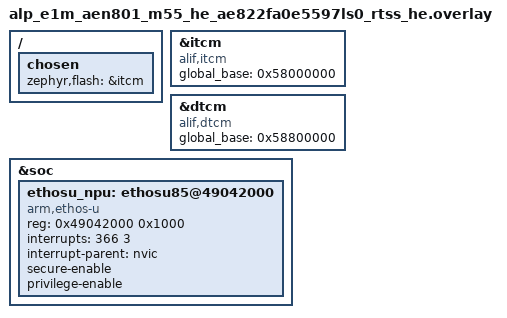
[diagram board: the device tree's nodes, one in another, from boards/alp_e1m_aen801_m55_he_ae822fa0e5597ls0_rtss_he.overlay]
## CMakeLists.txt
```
# Copyright (c) 2026 Alp Lab AB
# SPDX-License-Identifier: Apache-2.0
#
# aen-inference-latency -- on-target inference LATENCY benchmark for the
# E1M-AEN801 / AEN803 (Ensemble E8, M55-HE).  Runs a Vela-compiled int8 model
# in timed windows and prints cycles + milliseconds per inference and the
# tensor-arena high-water mark.  No rail monitor, no I2C: it needs nothing but
# the console, so it runs on any board and fits the Flow C ITCM RAM-run path
# for small models.  Its console protocol is the ENERGY-CFG / ENERGY-W subset
# that `tan model run --device --capture` parses (see src/main.cpp).
#
# The NPU build wiring is IDENTICAL to examples/aen/aen-inference-energy and
# the silicon-proven examples/aen/aen-npu-inference-alif, and reuses that
# app's gen_model.py rather than copying it (one Vela invocation, one hardware
# fact).  Only the model-gen script is shared; every config file here is local.
#
# Modules required at build time (pass via -DEXTRA_ZEPHYR_MODULES):
#   the alp-sdk checkout, hal_alif, hal/ethos_u, lib/tflite-micro
# the AEN bench build helper passes the first two automatically.

cmake_minimum_required(VERSION 3.20.0)

find_package(Zephyr REQUIRED HINTS $ENV{ZEPHYR_BASE})
project(aen_inference_latency LANGUAGES C CXX)

set(AEN_NPU_INFERENCE_DIR "${CMAKE_CURRENT_SOURCE_DIR}/../aen-npu-inference-alif"
    CACHE PATH "Sibling example whose gen_model.py (the Vela driver) is SHARED, not copied")

# Fail with the actual reason.  Copying this example out of the SDK tree -- the
# normal customer path -- leaves the sibling behind, and without this check the
# build dies as an opaque "model-gen failed (rc=1)" from the custom command.
if(NOT EXISTS "${AEN_NPU_INFERENCE_DIR}/gen_model.py")
	message(FATAL_ERROR
		"aen-inference-latency: cannot find ${AEN_NPU_INFERENCE_DIR}/gen_model.py.\n"
		"This example deliberately SHARES the Vela driver script with "
		"examples/aen/aen-npu-inference-alif rather than copying it, so the two "
		"cannot drift.  Keep both example directories together, or point "
		"-DAEN_NPU_INFERENCE_DIR=<path to aen-npu-inference-alif> at it.")
endif()

# --------------------------------------------------------------------------
# Model-gen: Vela-compile the fixture for the U85 with the Alif system-config.
# --------------------------------------------------------------------------
set(AEN_NPU_VELA   "vela"
    CACHE FILEPATH "Vela compiler executable (on PATH, or override: -DAEN_NPU_VELA=<venv>/bin/vela)")
set(AEN_NPU_ACCEL  "ethos-u85-256"
    CACHE STRING   "Vela --accelerator-config (the AEN801 U85 is 256-MAC)")
set(AEN_NPU_MODEL  "${CMAKE_CURRENT_SOURCE_DIR}/../../../tests/fixtures/models/tiny_int8.tflite"
    CACHE FILEPATH "Input int8 .tflite to Vela-compile")
set(AEN_NPU_MODEL_NAME "tiny_int8_fixture"
    CACHE STRING   "Embedded model identity string")

# ALIF PROPRIETARY Vela config -- NOT redistributed by alp-sdk.  Obtain it from
# alp-sdk-internal and pass -DAEN_NPU_VELA_CONFIG=<path>/ensemble_vela.ini.
# When unset, Vela uses its built-in system-config; the app still runs on the
# NPU (src/main.cpp pins every region to the SRAM AXI port, which is what the
# SRAM_Only layout needs), but the command stream is not the bench-matched one.
set(AEN_NPU_VELA_CONFIG ""
    CACHE FILEPATH "Path to the Alif Vela config .ini (ALIF PROPRIETARY -- from alp-sdk-internal)")
set(AEN_NPU_SYSTEM_CONFIG "Ethos_U85_SRAM_Only"
    CACHE STRING   "Vela --system-config (HE core, single SRAM region)")
set(AEN_NPU_MEMORY_MODE   "Sram_Only"
    CACHE STRING   "Vela --memory-mode (single region -> SRAM0)")

set(AEN_NPU_GEN_DIR "${CMAKE_CURRENT_BINARY_DIR}/model-gen")
set(AEN_NPU_MODEL_H "${AEN_NPU_GEN_DIR}/model.h")

set(_gen_args
	--vela          ${AEN_NPU_VELA}
	--accel         ${AEN_NPU_ACCEL}
	--model         ${AEN_NPU_MODEL}
	--name          ${AEN_NPU_MODEL_NAME}
	--build-dir     ${AEN_NPU_GEN_DIR}
	--out           ${AEN_NPU_MODEL_H}
)
# --system-config/--memory-mode name sections that live ONLY in the Alif
# proprietary ensemble_vela.ini, so pass them ONLY when that config is supplied
# -- else Vela errors "Section ... not found" against its built-in vela.ini.
if(AEN_NPU_VELA_CONFIG)
	list(APPEND _gen_args --config ${AEN_NPU_VELA_CONFIG}
	     --system-config ${AEN_NPU_SYSTEM_CONFIG} --memory-mode ${AEN_NPU_MEMORY_MODE})
endif()

add_custom_command(
	OUTPUT  ${AEN_NPU_MODEL_H}
	COMMAND ${CMAKE_COMMAND} -E make_directory ${AEN_NPU_GEN_DIR}
	COMMAND ${PYTHON_EXECUTABLE} ${AEN_NPU_INFERENCE_DIR}/gen_model.py ${_gen_args}
	DEPENDS ${AEN_NPU_MODEL} ${AEN_NPU_INFERENCE_DIR}/gen_model.py
	COMMENT "aen-inference-latency: Vela-compiling ${AEN_NPU_MODEL} for ${AEN_NPU_ACCEL}"
	VERBATIM
)

# Configure-time generation (so the include path resolves on the first build).
if(NOT EXISTS ${AEN_NPU_MODEL_H})
	execute_process(
		COMMAND ${CMAKE_COMMAND} -E make_directory ${AEN_NPU_GEN_DIR}
		COMMAND ${PYTHON_EXECUTABLE} ${AEN_NPU_INFERENCE_DIR}/gen_model.py ${_gen_args}
		RESULT_VARIABLE _gen_rc
	)
	if(NOT _gen_rc EQUAL 0)
		message(FATAL_ERROR "aen-inference-latency: model-gen failed (rc=${_gen_rc})")
	endif()
endif()

add_custom_target(aen_latency_model DEPENDS ${AEN_NPU_MODEL_H})
add_dependencies(app aen_latency_model)

# Publish hal_alif's common/include so <soc_memory_map.h> (local_to_global())
# resolves.  hal_alif adds it only under CONFIG_RTSS_HE/HP, but that same gate
# also compiles TrustZone sources that hard-#error without a non-secure DTS
# node this RAM-run board does not have -- so publish just the headers.
zephyr_include_directories(${ZEPHYR_ALIF_MODULE_DIR}/common/include)

target_include_directories(app PRIVATE ${AEN_NPU_GEN_DIR})
target_sources(app PRIVATE src/main.cpp)

# --------------------------------------------------------------------------
# Benchmark knobs -> preprocessor defines.  A `-DFOO=bar` on the cmake command
# line only sets a CACHE variable; it reaches the compiler only through this
# forwarding.  Each is left EMPTY so src/main.cpp keeps its own #ifndef default.
# --------------------------------------------------------------------------
set(AEN_LATENCY_WINDOWS "" CACHE STRING
    "Timed windows to run (default 5, max 6: RAM console size)")
set(AEN_LATENCY_INFERENCES "" CACHE STRING
    "Inferences per window (default 20)")
set(AEN_LATENCY_WINDOW_MAX_MS "" CACHE STRING
    "Per-window wall-time cap in ms, must stay under the 26.8 s cycle-counter wrap (default 10000)")

foreach(_knob AEN_LATENCY_WINDOWS AEN_LATENCY_INFERENCES AEN_LATENCY_WINDOW_MAX_MS)
	if(NOT "${${_knob}}" STREQUAL "")
		target_compile_definitions(app PRIVATE ${_knob}=${${_knob}})
		message(STATUS "aen-inference-latency: ${_knob}=${${_knob}}")
	endif()
endforeach()
```

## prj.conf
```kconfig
# SPDX-License-Identifier: Apache-2.0
#
# aen-inference-latency -- per-inference latency of a Vela-compiled model on the
# E1M-AEN801 / AEN803 Ethos-U85 (M55-HE).  The NPU stack below is transcribed
# from examples/aen/aen-inference-energy / aen-npu-inference-alif
# (silicon-proven); this app adds no I2C and no chip driver.

# --- TFLM + Ethos-U stack (see aen-npu-inference-alif for the derivation) ---

# TFLM is C++17; the MicroInterpreter is C++.
CONFIG_CPP=y
CONFIG_STD_CPP17=y

# TFLM module + the Ethos-U custom-op kernel that dispatches onto the NPU.
CONFIG_TENSORFLOW_LITE_MICRO=y

# The Arm Ethos-U core driver + the Zephyr frontend that instantiates the
# arm,ethos-u node at POST_KERNEL.  CONFIG_ARM_ETHOS_U stays unset for the same
# reason as aen-inference-energy: src/main.cpp provides the address remap.
CONFIG_ETHOS_U=y
CONFIG_ETHOS_U_DCACHE=y

# The AE822 (E8) NPU is an Ethos-U85, 256-MAC.
CONFIG_ETHOS_U85_256=y

# --- Heap / stack -----------------------------------------------------------

CONFIG_HEAP_MEM_POOL_SIZE=65536
CONFIG_MAIN_STACK_SIZE=16384

# --- DMA correctness --------------------------------------------------------

# The NPU is a DMA master; DCACHE=n keeps the CPU and NPU views coherent.
CONFIG_DCACHE=n

# --- Console: RAM console ----------------------------------------------------

# The whole capture is a few KB (header + one ENERGY-W and a handful of
# per-inference lines per window), so 8 KiB with headroom replaces
# aen-inference-energy's 64 KiB sample-stream buffer.  A truncated RAM console
# reads as a shorter capture, so the size is generous on purpose.  The buffer is
# DTCM (not the ITCM image), so it does not eat the Flow C budget.
# Read back with the AEN RAM-run helper; for a large model use the Flow D
# overlay in flowd/ and read the console over SWD/UART as usual.
CONFIG_CONSOLE=y
CONFIG_RAM_CONSOLE=y
CONFIG_RAM_CONSOLE_BUFFER_SIZE=8192
CONFIG_UART_CONSOLE=n
CONFIG_STDOUT_CONSOLE=y
CONFIG_PRINTK=y

# ms-per-inference is printed as a decimal; the ENERGY-CFG header carries the
# measured arena sizes as integers, but the per-window mean latency uses %f.
CONFIG_CBPRINTF_FP_SUPPORT=y

# Logging off: deferred log mode has no ram_console backend and would eat the
# printk protocol lines.
CONFIG_LOG=n
```

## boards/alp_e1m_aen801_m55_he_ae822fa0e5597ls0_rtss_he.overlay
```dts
/*
 * Copyright (c) 2026 Alp Lab AB
 * SPDX-License-Identifier: Apache-2.0
 *
 * aen-inference-latency overlay for the E1M-AEN801 (Ensemble E8, M55-HE)
 * bench RAM-run.  Only the NPU half of aen-inference-energy's overlay: the
 * ITCM retarget + itcm/dtcm global_base + the Ethos-U85 node, transcribed from
 * examples/aen/aen-npu-inference-alif (silicon-proven).  There is deliberately
 * no I2C2 / pinctrl half -- this app has no rail monitor.
 */
/*
 * RAM-run: the SoC `select` puts code in XIP; retarget ROM to ITCM so the
 * image links + runs from RAM (J-Link loadbin+go, no reset).  PATH-REFERENCE
 * form (&itcm) -- the phandle-array form <&itcm> makes FLASH_SIZE=0 and the
 * image overflows the (empty) FLASH region at link time.
 */
/ {
	chosen {
		zephyr,flash = &itcm;
		/delete-property/ zephyr,code-partition;
	};
};

/*
 * global_base for hal_alif's local_to_global() (soc_memory_map.h), which the
 * strong ethosu_address_remap in src/main.cpp calls.  The board's upstream
 * itcm/dtcm nodes are compatible "arm,itcm"/"arm,dtcm", whose binding has no
 * global_base, so re-`compatible` them onto the alp-sdk alif,itcm/alif,dtcm
 * bindings (which declare it) and set the E8 RTSS-HE global views, transcribed
 * from the Apache-2.0 zephyr_alif fork
 * (dts/arm/alif/ensemble/common/ensemble_rtss_he.dtsi):
 *     ITCM global_base = 0x58000000, DTCM global_base = 0x58800000.
 * reg / zephyr,memory-region are unchanged, so the linker regions and the
 * RAM-run retarget above are unaffected.
 */
&itcm {
	compatible = "alif,itcm";
	global_base = <0x58000000>;
};

&dtcm {
	compatible = "alif,dtcm";
	global_base = <0x58800000>;
};

&soc {
	/*
	 * Arm Ethos-U85 NPU.  compatible "arm,ethos-u", driven by the Arm
	 * Ethos-U core driver's Zephyr frontend (drivers/misc/ethos_u).
	 * Base 0x49042000, IRQ 366 + secure/privilege flags transcribed
	 * verbatim from the fork node (e4_e6_e8.dtsi ethosu1).  No `clocks`
	 * property: the fork's ethosu85 node carries none, and regcheck already
	 * confirmed the block is clocked (device_is_ready=1, ID=0x20007001).
	 */
	ethosu_npu: ethosu85@49042000 {
		compatible = "arm,ethos-u";
		reg = <0x49042000 0x1000>;
		interrupts = <366 3>;
		interrupt-parent = <&nvic>;
		secure-enable;
		privilege-enable;
		status = "okay";
	};
};
```

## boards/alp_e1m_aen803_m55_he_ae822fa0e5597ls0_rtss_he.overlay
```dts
/*
 * Copyright (c) 2026 Alp Lab AB
 * SPDX-License-Identifier: Apache-2.0
 *
 * aen-inference-latency overlay for the E1M-AEN803 (Ensemble E8, M55-HE)
 * bench RAM-run.  Only the NPU half of aen-inference-energy's overlay: the
 * ITCM retarget + itcm/dtcm global_base + the Ethos-U85 node, transcribed from
 * examples/aen/aen-npu-inference-alif (silicon-proven).  There is deliberately
 * no I2C2 / pinctrl half -- this app has no rail monitor.
 */
/*
 * RAM-run: the SoC `select` puts code in XIP; retarget ROM to ITCM so the
 * image links + runs from RAM (J-Link loadbin+go, no reset).  PATH-REFERENCE
 * form (&itcm) -- the phandle-array form <&itcm> makes FLASH_SIZE=0 and the
 * image overflows the (empty) FLASH region at link time.
 */
/ {
	chosen {
		zephyr,flash = &itcm;
		/delete-property/ zephyr,code-partition;
	};
};

/*
 * global_base for hal_alif's local_to_global() (soc_memory_map.h), which the
 * strong ethosu_address_remap in src/main.cpp calls.  The board's upstream
 * itcm/dtcm nodes are compatible "arm,itcm"/"arm,dtcm", whose binding has no
 * global_base, so re-`compatible` them onto the alp-sdk alif,itcm/alif,dtcm
 * bindings (which declare it) and set the E8 RTSS-HE global views, transcribed
 * from the Apache-2.0 zephyr_alif fork
 * (dts/arm/alif/ensemble/common/ensemble_rtss_he.dtsi):
 *     ITCM global_base = 0x58000000, DTCM global_base = 0x58800000.
 * reg / zephyr,memory-region are unchanged, so the linker regions and the
 * RAM-run retarget above are unaffected.
 */
&itcm {
	compatible = "alif,itcm";
	global_base = <0x58000000>;
};

&dtcm {
	compatible = "alif,dtcm";
	global_base = <0x58800000>;
};

&soc {
	/*
	 * Arm Ethos-U85 NPU.  compatible "arm,ethos-u", driven by the Arm
	 * Ethos-U core driver's Zephyr frontend (drivers/misc/ethos_u).
	 * Base 0x49042000, IRQ 366 + secure/privilege flags transcribed
	 * verbatim from the fork node (e4_e6_e8.dtsi ethosu1).  No `clocks`
	 * property: the fork's ethosu85 node carries none, and regcheck already
	 * confirmed the block is clocked (device_is_ready=1, ID=0x20007001).
	 */
	ethosu_npu: ethosu85@49042000 {
		compatible = "arm,ethos-u";
		reg = <0x49042000 0x1000>;
		interrupts = <366 3>;
		interrupt-parent = <&nvic>;
		secure-enable;
		privilege-enable;
		status = "okay";
	};
};
```

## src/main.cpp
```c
/*
 * Copyright (c) 2026 Alp Lab AB
 * SPDX-License-Identifier: Apache-2.0
 *
 * aen-inference-latency -- how long does ONE Ethos-U inference take?
 *
 * A latency-only sibling of aen-inference-energy.  It needs no INA236 rail
 * monitor, no I2C and no chip driver: only the M55 cycle counter and the
 * console.  It runs the embedded, Vela-compiled model in W timed windows of N
 * back-to-back inferences and reports, per window, the total span in CPU cycles
 * and milliseconds and the inference count -- plus every inference's own cycle
 * count (the first LAT_DETAIL of each window) and the tensor-arena high-water
 * mark.  Nothing is printed inside a window, so the console never lands in the
 * timed interval.
 *
 * WHAT THE NUMBER IS.  Wall time of the whole window loop divided by the
 * inferences it completed: Invoke() end to end (Ethos-U command-stream build,
 * NPU run, interrupt, output hand-off, plus any CPU fallback ops), warm, with
 * the model already allocated.  It is NOT the NPU's pure-compute time, and it
 * excludes the one-off AllocateTensors / warm-up call.
 *
 * CONSOLE PROTOCOL (the contract with `tan model run --device --capture`).
 * The lines below are a strict subset of aen-inference-energy's ENERGY-*
 * protocol, byte-for-byte, so the same parser reads both apps:
 *
 *   ENERGY-CFG {json}                   once, before any window
 *       required keys: cycles_per_s (CPU Hz, > 0), npu_dispatched (bool)
 *       extra keys (ignored by the parser, kept for humans): mode, model,
 *       model_bytes, arena_used_bytes, arena_bytes, sram_peak_bytes,
 *       windows, inferences_per_window, timestamp_source
 *   ENERGY-W <w> active 0 <span_cycles> <span_ms> <inferences>
 *                                       once per window; 0 = no sample stream
 *   ENERGY-WERR <w> active timed_out=1 ...   a failed window (excluded by tan)
 *   ENERGY-WARN active window <ms> ms exceeds the cycle-counter wrap ...
 *
 * There is no idle phase, no ENERGY-S stream and no rail / power_lsb_w key, so
 * the parser derives latency only and reports no energy -- by construction.
 *
 * Extra lines the parser skips as noise (never ENERGY-* prefixed):
 *   LATENCY-I <w> <j> <cycles>          one inference's own cycle count (DWT)
 *   LATENCY-WSTAT <w> n=.. min=.. max=.. mean=.. cyccnt_stalled=0|1
 *   LATENCY-WARN ...                    DWT detail dropped for a window
 *   DWT-DIAG w=.. stalled=.. ...        trace-block register snapshot
 *   LATENCY-RESULT {json} / RESULT PASS|FAIL: ...
 *
 * CLOCKS.  Every span (ENERGY-W span_cycles, the mean, the RESULT line) comes
 * from k_cycle_get_32(): the SysTick-backed kernel cycle counter
 * (CONFIG_CORTEX_M_SYSTICK=y, 160000000 Hz).  It keeps running when a debugger
 * detaches.  The DWT CYCCNT froze mid-window on the bench (a J-Link close
 * rewrites DEMCR / debug-domain gating), so firmware must not depend on it: it
 * is used ONLY for the per-inference LATENCY-I detail and min/max, is re-armed
 * and checked at every window start, and its numbers are dropped for any window
 * where it stalls or disagrees with the kernel span by more than 2 %.
 *
 * Both counters are uint32 and wrap every 2^32 / 160 MHz = 26.8 s, so a window
 * is closed at AEN_LATENCY_WINDOW_MAX_MS (default 10 s) even if fewer than N
 * inferences ran.  Only a SINGLE inference longer than the wrap is
 * unmeasurable; that case is reported with an ENERGY-WARN line.
 */

#include <cstdint>
#include <cstring>
#include <new>

#include <zephyr/kernel.h>
#include <zephyr/device.h>
#include <zephyr/devicetree.h>
#include <zephyr/sys/printk.h>

#include <cmsis_core.h>

/* hal_alif local_to_global() -- ITCM/DTCM CPU-local -> NPU global view. */
#include <soc_memory_map.h>

#include <tensorflow/lite/micro/micro_interpreter.h>
#include <tensorflow/lite/micro/micro_mutable_op_resolver.h>
#include <tensorflow/lite/schema/schema_generated.h>

/* Generated by ../aen-npu-inference-alif/gen_model.py: networkModelData[],
 * NETWORK_MODEL_LEN, NETWORK_MODEL_NAME, TENSOR_ARENA_SIZE, and the SRAM0
 * placement macros (MODEL_ATTR / TENSOR_ARENA_ATTR / NPU_ALIGN). */
#include "model.h"

#define NPU_NODE DT_NODELABEL(ethosu_npu)

/* ------------------------------------------------------------------------- *
 * Ethos-U strong overrides, transcribed from examples/aen/aen-npu-inference-alif
 * (see that app's src/main.cpp for the derivation).  They must be STRONG
 * definitions in the application image to override the core driver's weak ones.
 * ------------------------------------------------------------------------- */

/* QBASE + every BASEP go through this hook; ITCM/DTCM buffers need the NPU's
 * global view, which is hal_alif's own local_to_global(). */
extern "C" uint64_t ethosu_address_remap(uint64_t address, int index)
{
	(void)index;
	return local_to_global((void *)(uint32_t)address);
}

/* MEM_ATTR index 0 = the NPU's SRAM AXI port; the Arm default (EXT port)
 * bus-aborts because the model, command stream and arena all live in SRAM0. */
extern "C" unsigned int ethosu_config_select(uint64_t address, int index)
{
	(void)address;
	(void)index;
	return 0U;
}

/* ------------------------------------------------------------------------- *
 * Benchmark parameters (override with -DAEN_LATENCY_*=..., see CMakeLists.txt).
 * ------------------------------------------------------------------------- */

#ifndef AEN_LATENCY_WINDOWS
#define AEN_LATENCY_WINDOWS 5
#endif
#ifndef AEN_LATENCY_INFERENCES
#define AEN_LATENCY_INFERENCES 20
#endif
/* Under the 26.8 s counter wrap at 160 MHz with a wide margin. */
#ifndef AEN_LATENCY_WINDOW_MAX_MS
#define AEN_LATENCY_WINDOW_MAX_MS 10000
#endif

static constexpr uint32_t WINDOWS       = AEN_LATENCY_WINDOWS;
static constexpr uint32_t INFERENCES    = AEN_LATENCY_INFERENCES;
static constexpr uint32_t WINDOW_MAX_MS = AEN_LATENCY_WINDOW_MAX_MS;

/* The DWT counter is a uint32: at 160 MHz it wraps after 26.843 s, so a window
 * must close before that. */
static_assert(AEN_LATENCY_WINDOW_MAX_MS >= 50 && AEN_LATENCY_WINDOW_MAX_MS < 26843,
              "AEN_LATENCY_WINDOW_MAX_MS must be in [50, 26843) ms (32-bit DWT wrap at 160 MHz)");

/* Worst-case console output per window is ~1 KB (32 LATENCY-I lines of up to
 * 27 B, one LATENCY-WSTAT, one ENERGY-W, one ENERGY-WERR) plus ~1.2 KB of
 * header and result lines; 6 windows stay under the 8 KiB RAM console in
 * prj.conf.  Raise CONFIG_RAM_CONSOLE_BUFFER_SIZE before raising this. */
static_assert(AEN_LATENCY_WINDOWS >= 1 && AEN_LATENCY_WINDOWS <= 6,
              "AEN_LATENCY_WINDOWS must be 1..6 to fit the 8 KiB RAM console");

/* A window also runs until it has lasted this long, so a model faster than the
 * 1 ms kernel clock still yields a span whose millisecond cross-check is within
 * ~2 % -- the parser compares the span-implied clock with the DT constant. */
static constexpr uint32_t WINDOW_MIN_MS = 50;

/* Per-inference cycle lines printed per window (the first N); the full set is
 * summarised by LATENCY-WSTAT.  Keeps the console capture a few KB. */
static constexpr uint32_t LAT_DETAIL = 32;

/* ------------------------------------------------------------------------- *
 * Clocks.  Kernel cycles (SysTick-backed) are authoritative; DWT CYCCNT is an
 * optional per-inference detail source that must never gate the measurement.
 * ------------------------------------------------------------------------- */

static bool g_dwt_present; /* DWT_CTRL.NOCYCCNT clear at boot */

static inline uint32_t kcycles(void)
{
	return k_cycle_get_32();
}

static inline uint32_t dwt_now(void)
{
	return DWT->CYCCNT;
}

/* Re-arm the trace block (a debugger detach can clear TRCENA / CYCCNTENA). */
static void dwt_rearm(void)
{
	if (!g_dwt_present) {
		return;
	}
	DCB->DEMCR |= DCB_DEMCR_TRCENA_Msk;
	DWT->CTRL |= DWT_CTRL_CYCCNTENA_Msk;
	__DSB();
}

/* True if CYCCNT advances across a short busy loop. */
static bool dwt_advancing(void)
{
	if (!g_dwt_present) {
		return false;
	}
	const uint32_t a = dwt_now();
	for (volatile int i = 0; i < 64; i++) {
		__NOP();
	}
	return dwt_now() != a;
}

static void dwt_init(void)
{
	DCB->DEMCR |= DCB_DEMCR_TRCENA_Msk;
	__DSB();
	g_dwt_present = !(DWT->CTRL & DWT_CTRL_NOCYCCNT_Msk);
	if (g_dwt_present) {
		DWT->CYCCNT = 0U;
		dwt_rearm();
	}
}

/* Privileged PPB reads for the DWT-DIAG line.  DAUTHSTATUS / DSCSR are
 * ARMv8-M architected registers addressed directly (CMSIS names vary). */
struct dwt_snap {
	uint32_t demcr, dwt_ctrl, cyccnt, dhcsr, dauth, dscsr;
	bool     taken;
};

static void dwt_snapshot(dwt_snap *d)
{
	d->demcr    = DCB->DEMCR;
	d->dwt_ctrl = DWT->CTRL;
	d->cyccnt   = DWT->CYCCNT;
	d->dhcsr    = DCB->DHCSR;
	d->dauth    = *(volatile uint32_t *)0xE000EFB8UL;
	d->dscsr    = *(volatile uint32_t *)0xE000EE08UL;
	d->taken    = true;
}

/* ------------------------------------------------------------------------- *
 * NPU-reachable buffers (SRAM0): the NPU cannot reach DTCM.  The model is
 * initialised rodata; Zephyr does not init-copy the SRAM0 custom section, so
 * the rodata copy is staged into an uninitialised SRAM0 buffer in main().
 * ------------------------------------------------------------------------- */
TENSOR_ARENA_ATTR static uint8_t tensor_arena[TENSOR_ARENA_SIZE];
static uint8_t model_sram[NETWORK_MODEL_LEN] __aligned(NPU_ALIGN) __attribute__((section("SRAM0")));

/* Latched evidence, readable by symbol over SWD even with no console. */
volatile int      g_alloc_status  = -1;
volatile int      g_invoke_status = -1;
volatile uint32_t g_total_inferences;

struct window_result {
	uint32_t    inferences;  /* completed inferences                          */
	uint32_t    span_cycles; /* whole-window span, KERNEL cycles (authoritative) */
	uint32_t    span_ms;     /* same window, kernel millisecond clock         */
	uint32_t    min_cycles;  /* fastest / slowest inference, DWT (detail only) */
	uint32_t    max_cycles;
	uint32_t    detail_n;    /* how many entries of g_detail are valid        */
	bool        failed;      /* an Invoke() returned non-OK                   */
	bool        dwt_ok;      /* DWT detail is trustworthy for this window     */
	const char *dwt_why;     /* why not (NULL if dwt_ok)                      */
	const char *reason;      /* NULL = window valid, else why it was rejected */
	int         rearm_adv;   /* -1 none, else DWT advanced after the re-arm   */
	dwt_snap    first, last; /* DWT-DIAG snapshots: first stall, window end   */
};

static uint32_t g_detail[LAT_DETAIL];

/* One timed window: invoke back to back until the count AND the minimum time
 * are met, or the maximum time is hit.  Nothing is printed in here. */
static void run_window(tflite::MicroInterpreter *interp, window_result *out)
{
	*out           = {};
	out->rearm_adv = -1;
	out->dwt_ok    = true;

	uint32_t n      = 0;
	uint32_t lo     = UINT32_MAX;
	uint32_t hi     = 0;
	uint32_t detail = 0;
	bool     failed = false;

	dwt_rearm();
	if (!dwt_advancing()) {
		out->dwt_ok  = false;
		out->dwt_why = "CYCCNT not advancing at window start";
		dwt_snapshot(&out->first);
		dwt_rearm();
		out->rearm_adv = dwt_advancing() ? 1 : 0;
	}

	const int64_t  t0_ms = k_uptime_get();
	const uint32_t t0_k  = kcycles();
	const uint32_t t0_d  = dwt_now();

	for (;;) {
		const int64_t elapsed_ms = k_uptime_get() - t0_ms;
		if (elapsed_ms >= (int64_t)WINDOW_MAX_MS) {
			break;
		}
		if (n >= INFERENCES && elapsed_ms >= (int64_t)WINDOW_MIN_MS) {
			break;
		}
		const uint32_t d0 = dwt_now();
		TfLiteStatus   st = interp->Invoke();
		const uint32_t dc = dwt_now() - d0;
		g_invoke_status   = (int)st;
		if (st != kTfLiteOk) {
			failed = true; /* a failing invoke must not be averaged in */
			break;
		}
		if (out->dwt_ok && dc == 0U) {
			/* A zero-cycle inference is a stalled counter, not a fast one. */
			out->dwt_ok  = false;
			out->dwt_why = "an inference read 0 DWT cycles";
			dwt_snapshot(&out->first);
			dwt_rearm();
			out->rearm_adv = dwt_advancing() ? 1 : 0;
		}
		if (out->dwt_ok) {
			if (detail < LAT_DETAIL) {
				g_detail[detail++] = dc;
			}
			if (dc < lo) {
				lo = dc;
			}
			if (dc > hi) {
				hi = dc;
			}
		}
		n++;
	}

	out->inferences         = n;
	out->span_cycles        = kcycles() - t0_k;
	const uint32_t dwt_span = dwt_now() - t0_d;
	out->span_ms            = (uint32_t)(k_uptime_get() - t0_ms);
	out->min_cycles         = (n > 0 && out->dwt_ok) ? lo : 0U;
	out->max_cycles         = out->dwt_ok ? hi : 0U;
	out->detail_n           = out->dwt_ok ? detail : 0U;
	out->failed             = failed;
	dwt_snapshot(&out->last);

	/* Cross-check the two clocks over the whole window (2 %). */
	if (out->dwt_ok && out->span_cycles > 0U) {
		const double k    = (double)out->span_cycles;
		const double diff = (double)dwt_span - k;
		if ((diff < 0 ? -diff : diff) > 0.02 * k) {
			out->dwt_ok  = false;
			out->dwt_why = "DWT span disagrees with kernel span by > 2 %";
			if (!out->first.taken) {
				out->first = out->last;
			}
			out->min_cycles = 0U;
			out->max_cycles = 0U;
			out->detail_n   = 0U;
		}
	}

	/* Kernel-only validity: the measurement is the kernel span. */
	if (failed) {
		out->reason = "Invoke() failed";
	} else if (n == 0U) {
		out->reason = "no inference completed";
	} else if (out->span_cycles == 0U) {
		out->reason = "kernel span_cycles == 0";
	}
}

static void print_snap(const char *tag, const dwt_snap &d)
{
	printk(" %s[demcr=%08x dwt_ctrl=%08x cyccnt=%08x dhcsr=%08x dauth=%08x dscsr=%08x]",
	       tag,
	       (unsigned)d.demcr,
	       (unsigned)d.dwt_ctrl,
	       (unsigned)d.cyccnt,
	       (unsigned)d.dhcsr,
	       (unsigned)d.dauth,
	       (unsigned)d.dscsr);
}

static void emit_window(uint32_t w, uint32_t cps, const window_result &r)
{
	/* A span longer than the counter wrap is indistinguishable from a real
	 * one, so say so rather than emit it silently. */
	if (r.span_ms > (uint32_t)(4294967295U / (cps / 1000U))) {
		printk("ENERGY-WARN active window %u ms exceeds the cycle-counter wrap -- "
		       "span_cycles is not meaningful; lower AEN_LATENCY_WINDOW_MAX_MS\n",
		       (unsigned)r.span_ms);
	}
	if (!r.dwt_ok) {
		printk("LATENCY-WARN window %u: DWT detail dropped (%s)\n",
		       (unsigned)w,
		       r.dwt_why != nullptr ? r.dwt_why : "?");
		printk("DWT-DIAG w=%u stalled=1 rearm_advanced=%d", (unsigned)w, r.rearm_adv);
		print_snap("first", r.first);
		print_snap("end", r.last);
		printk("\n");
	} else {
		printk("DWT-DIAG w=%u stalled=0", (unsigned)w);
		print_snap("end", r.last);
		printk("\n");
	}
	if (r.reason != nullptr) {
		printk("ENERGY-WERR %u active timed_out=1 reason=\"%s\" invoke_status=%d "
		       "completed=%u span_cycles=%u span_ms=%u\n",
		       (unsigned)w,
		       r.reason,
		       g_invoke_status,
		       (unsigned)r.inferences,
		       (unsigned)r.span_cycles,
		       (unsigned)r.span_ms);
		return;
	}
	/* The parser rejects a zero span, so clamp a sub-millisecond window to 1. */
	const unsigned span_ms = r.span_ms > 0U ? (unsigned)r.span_ms : 1U;
	for (uint32_t j = 0; j < r.detail_n; j++) {
		printk("LATENCY-I %u %u %u\n", (unsigned)w, (unsigned)j, (unsigned)g_detail[j]);
	}
	if (r.dwt_ok) {
		printk("LATENCY-WSTAT %u n=%u min=%u max=%u mean=%u cyccnt_stalled=0\n",
		       (unsigned)w,
		       (unsigned)r.inferences,
		       (unsigned)r.min_cycles,
		       (unsigned)r.max_cycles,
		       (unsigned)(r.span_cycles / r.inferences));
	} else {
		printk("LATENCY-WSTAT %u n=%u mean=%u cyccnt_stalled=1\n",
		       (unsigned)w,
		       (unsigned)r.inferences,
		       (unsigned)(r.span_cycles / r.inferences));
	}
	printk("ENERGY-W %u active 0 %u %u %u\n",
	       (unsigned)w,
	       (unsigned)r.span_cycles,
	       span_ms,
	       (unsigned)r.inferences);
}

int main(void)
{
	printk("\n=== aen-inference-latency ===\n");
	printk("model      : %s (%u bytes)\n", NETWORK_MODEL_NAME, (unsigned)NETWORK_MODEL_LEN);

	dwt_init();
	/* cycles_per_s is the kernel's hw cycle rate; the E8 M55-HE runs at
	 * 160000000.  The host parser cross-checks it against the span-implied
	 * rate, and the bench run must read exactly 160000000 here. */
	const uint32_t cps = sys_clock_hw_cycles_per_sec();
	if (cps != 160000000U) {
		printk("WARN: cycles_per_s=%u is not the expected 160000000 (E8 M55-HE)\n", (unsigned)cps);
	}
	printk("clock      : %u Hz, spans from k_cycle_get_32 (SysTick), detail from DWT CYCCNT (%s)\n",
	       (unsigned)cps,
	       g_dwt_present ? "present" : "absent");

	const struct device *npu       = DEVICE_DT_GET(NPU_NODE);
	const bool           npu_ready = device_is_ready(npu);
	printk(
	    "npu ready  : %d (Ethos-U85 @0x%08x)\n", (int)npu_ready, (unsigned)DT_REG_ADDR(NPU_NODE));

	/* Built ONCE, invoked many times: rebuilding the interpreter per iteration
	 * would fold model parsing and tensor allocation into the measured window. */
	memcpy(model_sram, networkModelData, NETWORK_MODEL_LEN);

	const tflite::Model *model = tflite::GetModel(model_sram);
	if (model->version() != TFLITE_SCHEMA_VERSION) {
		printk("RESULT FAIL: model schema %u != supported %d\n",
		       (unsigned)model->version(),
		       TFLITE_SCHEMA_VERSION);
		return 0;
	}

	/* Resolver and interpreter live in static storage via placement new and are
	 * never destroyed: a stack-local interpreter's destructor would re-walk the
	 * model flatbuffer in SRAM0 on return, which faults when another core has
	 * reused SRAM0 (#2318, same reasoning as aen-inference-energy). */
	alignas(tflite::MicroMutableOpResolver<8>) static uint8_t
	    resolver_storage[sizeof(tflite::MicroMutableOpResolver<8>)];
	alignas(tflite::MicroInterpreter) static uint8_t
	    interpreter_storage[sizeof(tflite::MicroInterpreter)];

	auto &resolver = *new (resolver_storage) tflite::MicroMutableOpResolver<8>();
	resolver.AddEthosU();
	resolver.AddReshape();
	resolver.AddConv2D();
	resolver.AddDepthwiseConv2D();
	resolver.AddFullyConnected();
	resolver.AddSoftmax();
	resolver.AddQuantize();
	resolver.AddDequantize();

	auto &interpreter = *new (interpreter_storage) tflite::MicroInterpreter(
	    model, resolver, tensor_arena, TENSOR_ARENA_SIZE);
	const TfLiteStatus alloc = interpreter.AllocateTensors();
	g_alloc_status           = (int)alloc;
	if (alloc != kTfLiteOk) {
		printk("RESULT FAIL: AllocateTensors=%d\n", (int)alloc);
		return 0;
	}
	TfLiteTensor *input = interpreter.input(0);
	memset(input->data.raw, 0, input->bytes);

	/* One warm-up invoke, outside every window: the first call reserves the
	 * Ethos-U driver and faults in code a steady state never repeats. */
	const TfLiteStatus warm = interpreter.Invoke();
	g_invoke_status         = (int)warm;
	if (warm != kTfLiteOk) {
		printk("RESULT FAIL: warm-up Invoke=%d (NPU dispatch failed) npu_ready=%d\n",
		       (int)warm,
		       (int)npu_ready);
		return 0;
	}
	printk("inference  : warm-up OK (input %u B, output %u B)\n",
	       (unsigned)input->bytes,
	       (unsigned)interpreter.output(0)->bytes);

	/* Peak SRAM0 use: the high-water mark of the tensor arena after
	 * AllocateTensors (the planner's real need, not the TENSOR_ARENA_SIZE
	 * reservation) plus the staged model copy that shares SRAM0 with it. */
	const unsigned arena_used = (unsigned)interpreter.arena_used_bytes();
	const unsigned sram_peak  = arena_used + (unsigned)NETWORK_MODEL_LEN;

	printk("ENERGY-CFG {\"mode\":\"latency-only\",\"cycles_per_s\":%u,"
	       "\"npu_dispatched\":%s,\"model\":\"%s\",\"model_bytes\":%u,"
	       "\"arena_used_bytes\":%u,\"arena_bytes\":%u,\"sram_peak_bytes\":%u,"
	       "\"windows\":%u,\"inferences_per_window\":%u,\"timestamp_source\":\"k-cycle-get-32\","
	       "\"detail_source\":\"%s\"}\n",
	       (unsigned)cps,
	       npu_ready ? "true" : "false",
	       NETWORK_MODEL_NAME,
	       (unsigned)NETWORK_MODEL_LEN,
	       arena_used,
	       (unsigned)TENSOR_ARENA_SIZE,
	       sram_peak,
	       (unsigned)WINDOWS,
	       (unsigned)INFERENCES,
	       g_dwt_present ? "dwt-cyccnt" : "none");

	uint32_t    total_inferences = 0;
	uint64_t    total_cycles     = 0;
	uint32_t    good_windows     = 0;
	const char *first_reason     = nullptr;
	uint32_t    first_bad        = 0;
	uint32_t    dwt_stalled      = 0;

	for (uint32_t w = 0; w < WINDOWS; w++) {
		window_result r = {};
		run_window(&interpreter, &r);
		emit_window(w, cps, r);
		if (!r.dwt_ok) {
			dwt_stalled++;
		}
		if (r.reason != nullptr) {
			if (first_reason == nullptr) {
				first_reason = r.reason;
				first_bad    = w;
			}
		} else {
			good_windows++;
			total_inferences += r.inferences;
			total_cycles += r.span_cycles;
		}
	}
	g_total_inferences = total_inferences;

	if (first_reason != nullptr || good_windows != WINDOWS || total_inferences == 0U) {
		printk("RESULT FAIL: window %u: %s (windows ok %u/%u) -- see ENERGY-WERR above\n",
		       (unsigned)first_bad,
		       first_reason != nullptr ? first_reason : "no inference completed",
		       (unsigned)good_windows,
		       (unsigned)WINDOWS);
		return 0;
	}

	const uint32_t cyc_per_inf = (uint32_t)(total_cycles / total_inferences);
	const double   ms_per_inf  = ((double)cyc_per_inf * 1000.0) / (double)cps;
	printk("LATENCY-RESULT {\"cycles_per_inference\":%u,\"ms_per_inference\":%f,"
	       "\"inferences\":%u,\"good_windows\":%u,\"windows\":%u,\"arena_used_bytes\":%u}\n",
	       (unsigned)cyc_per_inf,
	       ms_per_inf,
	       (unsigned)total_inferences,
	       (unsigned)good_windows,
	       (unsigned)WINDOWS,
	       arena_used);
	/* Kernel-clock numbers are valid even when the DWT detail stalled, so that
	 * is a PASS carrying a WARN, not a FAIL. */
	printk("RESULT PASS: %u cycles/inference (%f ms) n=%u windows=%u/%u arena_used=%u B%s\n",
	       (unsigned)cyc_per_inf,
	       ms_per_inf,
	       (unsigned)total_inferences,
	       (unsigned)good_windows,
	       (unsigned)WINDOWS,
	       arena_used,
	       dwt_stalled > 0U ? " WARN: DWT CYCCNT detail dropped (see LATENCY-WARN/DWT-DIAG)" : "");
	return 0;
}
```
